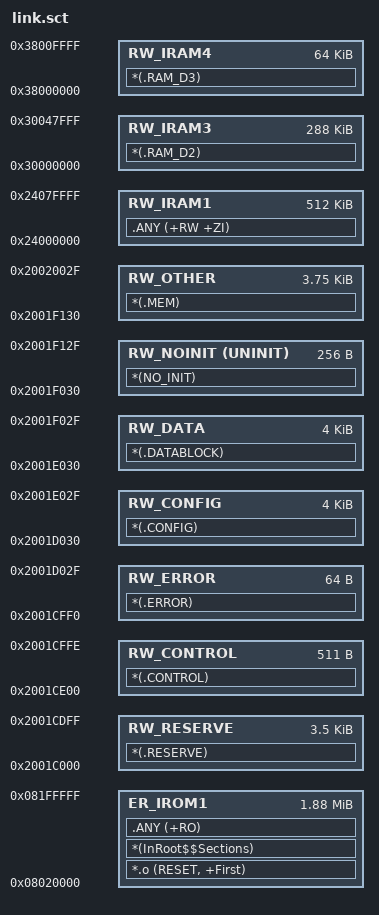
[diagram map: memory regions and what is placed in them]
; *************************************************************
; *** Scatter-Loading Description File generated by uVision ***
; *************************************************************

;LR_IROM1 0x08000000 0x00200000  {    ; load region size_region
;  ER_IROM1 0x08000000 0x00200000  {  ; load address = execution address
;   *.o (RESET, +First)
;   *(InRoot$$Sections)
;   .ANY (+RO)
;  }

LR_IROM1 0x08020000 0x001E0000  {    ; load region size_region
  ER_IROM1 0x08020000 0x001E0000  {  ; load address = execution address
   *.o (RESET, +First)
   *(InRoot$$Sections)
   .ANY (+RO)
  }

;  RW_IRAM2 0x20000000 0x00020000  {  ; RW data - 128KB DTCM
;   *(.RAM_DTCM) 
;  }

  RW_RESERVE 0x2001C000 0x00000E00  {
   *(.RESERVE)
  }
  RW_CONTROL 0x2001CE00 0x000001FF  {
   *(.CONTROL)
  }
  RW_ERROR 0x2001CFF0 0x00000040  {
   *(.ERROR)
  }
  RW_CONFIG 0x2001D030 0x00001000  {
   *(.CONFIG)
  }
  RW_DATA 0x2001E030 0x00001000  {
   *(.DATABLOCK)
  }
  RW_NOINIT 0x2001F030 UNINIT 0x00000100 {
    *(NO_INIT)
  }
  RW_OTHER 0x2001F130 0x00000F00  {
    *(.MEM)
  }






  RW_IRAM1 0x24000000 0x00080000  {  ; RW data
   .ANY (+RW +ZI)
  }
  RW_IRAM3 0x30000000 0x00048000  {  ; RW data - 128KB SRAM1(0x30000000) + 128KB SRAM2(0x3002 0000) + 32KB SRAM3(0x30040000)
   *(.RAM_D2)
  }
  
  RW_IRAM4 0x38000000 0x00010000  {  ; RW data - 64KB SRAM4(0x38000000)
   *(.RAM_D3)
  }
}



